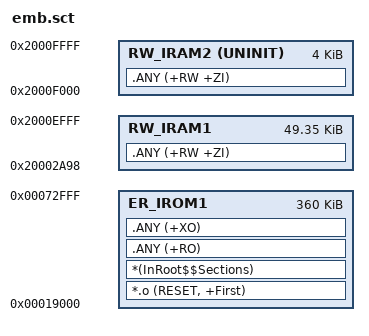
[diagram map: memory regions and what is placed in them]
; *************************************************************
; *** Scatter-Loading Description File generated by uVision ***
; *************************************************************

LR_IROM1 0x00019000 0x0005A000  {    ; load region size_region
  ER_IROM1 0x00019000 0x0005A000  {  ; load address = execution address
   *.o (RESET, +First)
   *(InRoot$$Sections)
   .ANY (+RO)
   .ANY (+XO)
  }
  RW_IRAM1 0x20002A98 0x0000C568  {  ; RW data
   .ANY (+RW +ZI)
  }
  RW_IRAM2 0x2000F000 UNINIT 0x00001000  {
   .ANY (+RW +ZI)
  }
}

